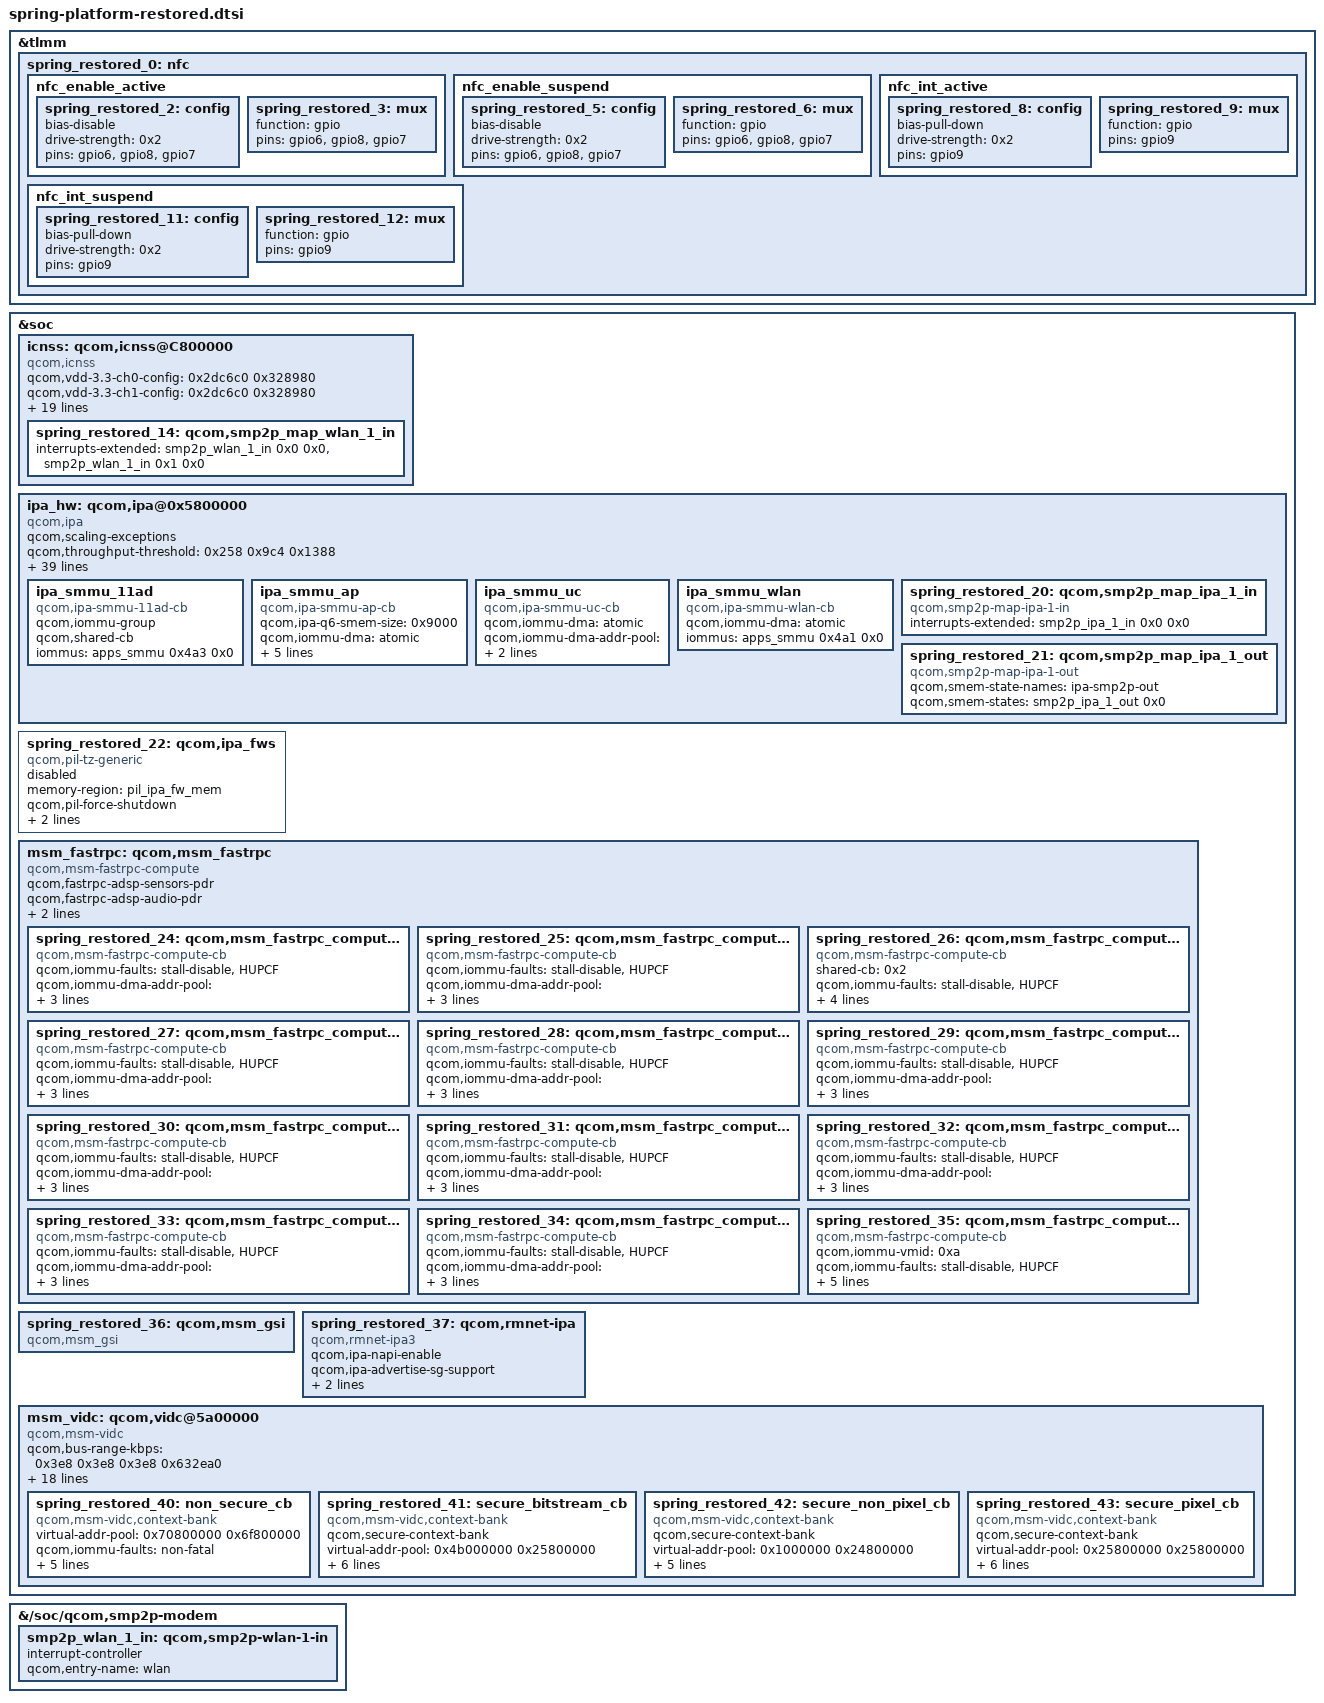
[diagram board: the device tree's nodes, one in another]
/*
 * Recovered from the confirmed working Spring DTB supplied in
 * infinity-17/device/xiaomi/spring-kernel/images (2026-11-06).
 * Missing platform sources are not present in this source checkout.
 * References are symbolic; no working-image phandle numbers are retained.
 */

&tlmm {
	spring_restored_0: nfc {
		nfc_enable_active: nfc_enable_active {
			spring_restored_2: config {
				bias-disable;
				drive-strength = <0x2>;
				pins = "gpio6", "gpio8", "gpio7";
			};
			spring_restored_3: mux {
				function = "gpio";
				pins = "gpio6", "gpio8", "gpio7";
			};
		};
		nfc_enable_suspend: nfc_enable_suspend {
			spring_restored_5: config {
				bias-disable;
				drive-strength = <0x2>;
				pins = "gpio6", "gpio8", "gpio7";
			};
			spring_restored_6: mux {
				function = "gpio";
				pins = "gpio6", "gpio8", "gpio7";
			};
		};
		nfc_int_active: nfc_int_active {
			spring_restored_8: config {
				bias-pull-down;
				drive-strength = <0x2>;
				pins = "gpio9";
			};
			spring_restored_9: mux {
				function = "gpio";
				pins = "gpio9";
			};
		};
		nfc_int_suspend: nfc_int_suspend {
			spring_restored_11: config {
				bias-pull-down;
				drive-strength = <0x2>;
				pins = "gpio9";
			};
			spring_restored_12: mux {
				function = "gpio";
				pins = "gpio9";
			};
		};
	};
};

&soc {
	icnss: qcom,icnss@C800000 {
		qcom,vdd-3.3-ch0-config = <0x2dc6c0 0x328980>;
		qcom,vdd-3.3-ch1-config = <0x2dc6c0 0x328980>;
		qcom,vdd-cx-mx-config = <0x9c400 0x9c400>;
		vdd-smps-supply = <&S5A>;
		vdd-3.3-ch0-supply = <&L23A>;
		vdd-3.3-ch1-supply = <&L21A>;
		vdd-1.3-rfa-supply = <&L2A>;
		vdd-1.8-xo-supply = <&L16A>;
		vdd-cx-mx-supply = <&L2E>;
		qcom,iommu-geometry = <0xa0000000 0x10010000>;
		qcom,iommu-dma-addr-pool = <0xa0000000 0x10000000>;
		qcom,wlan-msa-fixed-region = <&pil_wlan_mem>;
		qcom,wlan;
		qcom,iommu-faults = "stall-disable", "HUPCF", "non-fatal";
		qcom,iommu-dma = "fastmap";
		interrupts = <0x0 0x166 0x4 0x0 0x167 0x4 0x0 0x168 0x4 0x0 0x169 0x4 0x0 0x16a 0x4 0x0 0x16b 0x4 0x0 0x16c 0x4 0x0 0x16d 0x4 0x0 0x16e 0x4 0x0 0x16f 0x4 0x0 0x170 0x4 0x0 0x171 0x4>;
		iommus = <&apps_smmu 0x80 0x1>;
		reg-names = "membase", "smmu_iova_ipa";
		reg = <0xc800000 0x800000 0xb0000000 0x10000>;
		compatible = "qcom,icnss";
		spring_restored_14: qcom,smp2p_map_wlan_1_in {
			interrupt-names = "qcom,smp2p-force-fatal-error", "qcom,smp2p-early-crash-ind";
			interrupts-extended = <&smp2p_wlan_1_in 0x0 0x0 &smp2p_wlan_1_in 0x1 0x0>;
		};
	};
};

&soc {
	ipa_hw: qcom,ipa@0x5800000 {
		qcom,scaling-exceptions;
		qcom,throughput-threshold = <0x258 0x9c4 0x1388>;
		qcom,bus-vector-names = "MIN", "SVS2", "SVS", "NOMINAL", "TURBO";
		qcom,turbo = <0x324b0 0x556eb4 0x324b0 0x15eb41 0x324b0 0x78000>;
		qcom,nominal = <0x324b0 0x3d0900 0x324b0 0xae101 0x324b0 0x78000>;
		qcom,svs = <0x13880 0x1e8480 0x13880 0x414c5 0x13880 0x1ad42>;
		qcom,svs2 = <0x13880 0x71868 0x13880 0x10bda 0x13880 0x1e>;
		qcom,no-vote = <0x0 0x0 0x0 0x0 0x0 0x0>;
		interconnect-names = "ipa_to_ebi1", "ipa_to_imem", "appss_to_ipa";
		interconnects = <&system_noc 0x1d &bimc 0x200 &system_noc 0x1d &system_noc 0x232 &bimc 0x0 &config_noc 0x218>;
		qcom,interconnect,num-paths = <0x3>;
		qcom,interconnect,num-cases = <0x5>;
		qcom,max_num_smmu_cb = <0x4>;
		clocks = <&rpmcc 0x44>;
		clock-names = "core_clk";
		qcom,tx-wrapper-cache-max-size = <0x190>;
		qcom,wan-rx-ring-size = <0xc0>;
		qcom,ipa-endp-delay-wa;
		qcom,rmnet-ctl-enable;
		qcom,wan-use-skb-page;
		qcom,lan-rx-napi;
		qcom,use-64-bit-dma-mask;
		qcom,arm-smmu;
		qcom,ipa-wdi2_over_gsi;
		qcom,ipa-wdi2;
		qcom,modem-cfg-emb-pipe-flt;
		qcom,use-ipa-tethering-bridge;
		qcom,ee = <0x0>;
		qcom,platform-type = <0x1>;
		qcom,ipa-hw-mode = <0x0>;
		qcom,ipa-hw-ver = <0x14>;
		interrupt-names = "ipa-irq", "gsi-irq";
		interrupts = <0x0 0x101 0x4 0x0 0x103 0x4>;
		memory-regions = <&pil_ipa_fw_mem>;
		firmware-names = "ipa_fws";
		pas-ids = <0xf>;
		reg-names = "ipa-base", "gsi-base";
		reg = <0x5800000 0x84000 0x5804000 0x23000>;
		compatible = "qcom,ipa";
		ipa_smmu_11ad: ipa_smmu_11ad {
			qcom,iommu-group;
			qcom,shared-cb;
			iommus = <&apps_smmu 0x4a3 0x0>;
			compatible = "qcom,ipa-smmu-11ad-cb";
		};
		ipa_smmu_ap: ipa_smmu_ap {
			qcom,ipa-q6-smem-size = <0x9000>;
			qcom,iommu-dma = "atomic";
			qcom,additional-mapping = <0xc123000 0xc123000 0x2000>;
			qcom,iommu-dma-addr-pool = <0x20000000 0x20000000>;
			iommus = <&apps_smmu 0x4a0 0x0>;
			compatible = "qcom,ipa-smmu-ap-cb";
		};
		ipa_smmu_uc: ipa_smmu_uc {
			qcom,iommu-dma = "atomic";
			qcom,iommu-dma-addr-pool = <0x20000000 0x20000000>;
			iommus = <&apps_smmu 0x4a2 0x0>;
			compatible = "qcom,ipa-smmu-uc-cb";
		};
		ipa_smmu_wlan: ipa_smmu_wlan {
			qcom,iommu-dma = "atomic";
			iommus = <&apps_smmu 0x4a1 0x0>;
			compatible = "qcom,ipa-smmu-wlan-cb";
		};
		spring_restored_20: qcom,smp2p_map_ipa_1_in {
			interrupt-names = "ipa-smp2p-in";
			interrupts-extended = <&smp2p_ipa_1_in 0x0 0x0>;
			compatible = "qcom,smp2p-map-ipa-1-in";
		};
		spring_restored_21: qcom,smp2p_map_ipa_1_out {
			qcom,smem-state-names = "ipa-smp2p-out";
			qcom,smem-states = <&smp2p_ipa_1_out 0x0>;
			compatible = "qcom,smp2p-map-ipa-1-out";
		};
	};
};

&soc {
	spring_restored_22: qcom,ipa_fws {
		status = "disabled";
		memory-region = <&pil_ipa_fw_mem>;
		qcom,pil-force-shutdown;
		qcom,firmware-name = "ipa_fws";
		qcom,pas-id = <0xf>;
		compatible = "qcom,pil-tz-generic";
	};
};

&soc {
	msm_fastrpc: qcom,msm_fastrpc {
		qcom,fastrpc-adsp-sensors-pdr;
		qcom,fastrpc-adsp-audio-pdr;
		qcom,adsp-remoteheap-vmid = <0x16 0x25>;
		qcom,rpc-latency-us = <0x263>;
		compatible = "qcom,msm-fastrpc-compute";
		spring_restored_24: qcom,msm_fastrpc_compute_cb1 {
			qcom,iommu-faults = "stall-disable", "HUPCF";
			qcom,iommu-dma-addr-pool = <0x80000000 0x78000000>;
			iommus = <&apps_smmu 0x1001 0x0>;
			label = "cdsprpc-smd";
			compatible = "qcom,msm-fastrpc-compute-cb";
		};
		spring_restored_25: qcom,msm_fastrpc_compute_cb10 {
			qcom,iommu-faults = "stall-disable", "HUPCF";
			qcom,iommu-dma-addr-pool = <0x80000000 0x78000000>;
			iommus = <&apps_smmu 0xa3 0x0>;
			label = "adsprpc-smd";
			compatible = "qcom,msm-fastrpc-compute-cb";
		};
		spring_restored_26: qcom,msm_fastrpc_compute_cb11 {
			shared-cb = <0x2>;
			qcom,iommu-faults = "stall-disable", "HUPCF";
			qcom,iommu-dma-addr-pool = <0x80000000 0x78000000>;
			iommus = <&apps_smmu 0xa4 0x0>;
			label = "adsprpc-smd";
			compatible = "qcom,msm-fastrpc-compute-cb";
		};
		spring_restored_27: qcom,msm_fastrpc_compute_cb12 {
			qcom,iommu-faults = "stall-disable", "HUPCF";
			qcom,iommu-dma-addr-pool = <0x80000000 0x78000000>;
			iommus = <&apps_smmu 0xa5 0x0>;
			label = "adsprpc-smd";
			compatible = "qcom,msm-fastrpc-compute-cb";
		};
		spring_restored_28: qcom,msm_fastrpc_compute_cb13 {
			qcom,iommu-faults = "stall-disable", "HUPCF";
			qcom,iommu-dma-addr-pool = <0x80000000 0x78000000>;
			iommus = <&apps_smmu 0xa6 0x0>;
			label = "adsprpc-smd";
			compatible = "qcom,msm-fastrpc-compute-cb";
		};
		spring_restored_29: qcom,msm_fastrpc_compute_cb14 {
			qcom,iommu-faults = "stall-disable", "HUPCF";
			qcom,iommu-dma-addr-pool = <0x80000000 0x78000000>;
			iommus = <&apps_smmu 0xa7 0x0>;
			label = "adsprpc-smd";
			compatible = "qcom,msm-fastrpc-compute-cb";
		};
		spring_restored_30: qcom,msm_fastrpc_compute_cb2 {
			qcom,iommu-faults = "stall-disable", "HUPCF";
			qcom,iommu-dma-addr-pool = <0x80000000 0x78000000>;
			iommus = <&apps_smmu 0x1002 0x0>;
			label = "cdsprpc-smd";
			compatible = "qcom,msm-fastrpc-compute-cb";
		};
		spring_restored_31: qcom,msm_fastrpc_compute_cb3 {
			qcom,iommu-faults = "stall-disable", "HUPCF";
			qcom,iommu-dma-addr-pool = <0x80000000 0x78000000>;
			iommus = <&apps_smmu 0x1003 0x0>;
			label = "cdsprpc-smd";
			compatible = "qcom,msm-fastrpc-compute-cb";
		};
		spring_restored_32: qcom,msm_fastrpc_compute_cb4 {
			qcom,iommu-faults = "stall-disable", "HUPCF";
			qcom,iommu-dma-addr-pool = <0x80000000 0x78000000>;
			iommus = <&apps_smmu 0x1004 0x0>;
			label = "cdsprpc-smd";
			compatible = "qcom,msm-fastrpc-compute-cb";
		};
		spring_restored_33: qcom,msm_fastrpc_compute_cb5 {
			qcom,iommu-faults = "stall-disable", "HUPCF";
			qcom,iommu-dma-addr-pool = <0x80000000 0x78000000>;
			iommus = <&apps_smmu 0x1005 0x0>;
			label = "cdsprpc-smd";
			compatible = "qcom,msm-fastrpc-compute-cb";
		};
		spring_restored_34: qcom,msm_fastrpc_compute_cb6 {
			qcom,iommu-faults = "stall-disable", "HUPCF";
			qcom,iommu-dma-addr-pool = <0x80000000 0x78000000>;
			iommus = <&apps_smmu 0x1006 0x0>;
			label = "cdsprpc-smd";
			compatible = "qcom,msm-fastrpc-compute-cb";
		};
		spring_restored_35: qcom,msm_fastrpc_compute_cb9 {
			qcom,iommu-vmid = <0xa>;
			qcom,iommu-faults = "stall-disable", "HUPCF";
			qcom,iommu-dma-addr-pool = <0x80000000 0x78000000>;
			iommus = <&apps_smmu 0x1009 0x0>;
			qcom,secure-context-bank;
			label = "cdsprpc-smd";
			compatible = "qcom,msm-fastrpc-compute-cb";
		};
	};
};

&soc {
	spring_restored_36: qcom,msm_gsi {
		compatible = "qcom,msm_gsi";
	};
};

&soc {
	spring_restored_37: qcom,rmnet-ipa {
		qcom,ipa-napi-enable;
		qcom,ipa-advertise-sg-support;
		qcom,ipa-platform-type-msm;
		qcom,rmnet-ipa-ssr;
		compatible = "qcom,rmnet-ipa3";
	};
};

&{/soc/qcom,smp2p-modem} {
	smp2p_wlan_1_in: qcom,smp2p-wlan-1-in {
		#interrupt-cells = <0x2>;
		interrupt-controller;
		qcom,entry-name = "wlan";
	};
};

&soc {
	msm_vidc: qcom,vidc@5a00000 {
		qcom,bus-range-kbps = <0x3e8 0x3e8 0x3e8 0x632ea0>;
		interconnects = <&bimc 0x0 &config_noc 0x22c &mmnrt_virt 0xf &bimc 0x200>;
		interconnect-names = "venus-cnoc", "venus-ddr";
		vidc,firmware-name = "venus_ecdsa";
		qcom,reg-presets = <0xb0080 0x0 0x3>;
		qcom,allowed-clock-rates = <0x7ed6b40 0xe4e1c00 0x11e1a300 0x16e36000>;
		qcom,clock-configs = <0x1 0x0 0x1 0x0 0x0>;
		qcom,proxy-clock-names = "core_clk", "bus_clk", "core0_clk", "core0_bus_clk", "throttle_clk";
		clocks = <&gcc 0xba &gcc 0xb4 &gcc 0xb8 &gcc 0xb2 &gcc 0xb7>;
		clock-ids = <0xba 0xb4 0xb8 0xb2 0xb7>;
		clock-names = "core_clk", "bus_clk", "core0_clk", "core0_bus_clk", "throttle_clk";
		venus-core0-supply = <&gcc_vcodec0_gdsc>;
		venus-supply = <&gcc_venus_gdsc>;
		#size-cells = <0x1>;
		#address-cells = <0x1>;
		pas-id = <0x9>;
		memory-region = <&pil_video_mem>;
		interrupts = <0x0 0xe1 0x4>;
		reg = <0x5a00000 0x200000>;
		status = "okay";
		compatible = "qcom,msm-vidc", "qcom,msm-vidc-blair", "qcom,msm-vidc-ar50lt";
		spring_restored_40: non_secure_cb {
			virtual-addr-pool = <0x70800000 0x6f800000>;
			qcom,iommu-faults = "non-fatal";
			qcom,iommu-dma-addr-pool = <0x70800000 0x6f800000>;
			iommus = <&apps_smmu 0xc60 0x0 &apps_smmu 0xc80 0x0>;
			label = "venus_ns";
			compatible = "qcom,msm-vidc,context-bank";
		};
		spring_restored_41: secure_bitstream_cb {
			qcom,secure-context-bank;
			virtual-addr-pool = <0x4b000000 0x25800000>;
			qcom,iommu-vmid = <0x9>;
			qcom,iommu-faults = "non-fatal";
			qcom,iommu-dma-addr-pool = <0x4b000000 0x25800000>;
			iommus = <&apps_smmu 0xc61 0x4>;
			label = "venus_sec_bitstream";
			compatible = "qcom,msm-vidc,context-bank";
		};
		spring_restored_42: secure_non_pixel_cb {
			qcom,secure-context-bank;
			virtual-addr-pool = <0x1000000 0x24800000>;
			qcom,iommu-vmid = <0xb>;
			qcom,iommu-faults = "non-fatal";
			qcom,iommu-dma-addr-pool = <0x1000000 0x24800000>;
			iommus = <&apps_smmu 0xc04 0xe0>;
			label = "venus_sec_non_pixel";
			compatible = "qcom,msm-vidc,context-bank";
		};
		spring_restored_43: secure_pixel_cb {
			qcom,secure-context-bank;
			virtual-addr-pool = <0x25800000 0x25800000>;
			qcom,iommu-vmid = <0xa>;
			qcom,iommu-faults = "non-fatal";
			qcom,iommu-dma-addr-pool = <0x25800000 0x25800000>;
			iommus = <&apps_smmu 0xc63 0x0>;
			label = "venus_sec_pixel";
			compatible = "qcom,msm-vidc,context-bank";
		};
	};
};
